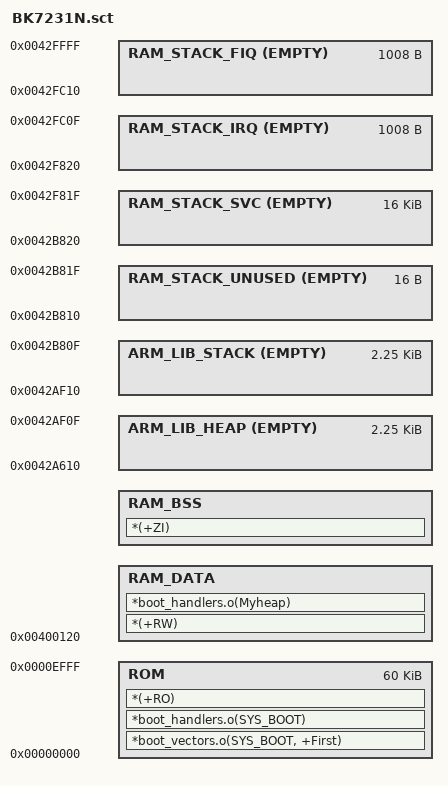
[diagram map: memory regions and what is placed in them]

SECTIONS 0x000000 (1024 * 60)
{
    ROM  0x000000 (1024 * 60)
    {
        *boot_vectors.o(SYS_BOOT, +First)		
        *boot_handlers.o(SYS_BOOT)
		
        *(+RO)
    } 
    
    RAM_DATA  0x400120
    {
        *(+RW)
		*boot_handlers.o(Myheap)
    } 
	
    RAM_BSS  +0
    {
        *(+ZI)
    } 
	
    ARM_LIB_HEAP 0x430000 - 0x3F0 - 0x3F0 - 0x4000 - 0x10 - 0x900 - 0x900  EMPTY 0x900
    {
    }

    ARM_LIB_STACK 0x430000 - 0x3F0 - 0x3F0 - 0x4000 - 0x10 - 0x900  EMPTY 0x900
    {
    }

    RAM_STACK_UNUSED 0x430000 - 0x3F0 - 0x3F0 - 0x4000 - 0x10  EMPTY 0x10
    {
    } 

    RAM_STACK_SVC 0x430000 - 0x3F0 - 0x3F0 - 0x4000  EMPTY 0x4000
    {
    } 

    RAM_STACK_IRQ 0x430000 - 0x3F0 - 0x3F0  EMPTY 0x3F0
    {
    } 

    RAM_STACK_FIQ 0x430000 - 0x3F0 EMPTY 0x3F0
    {
    }   
}

